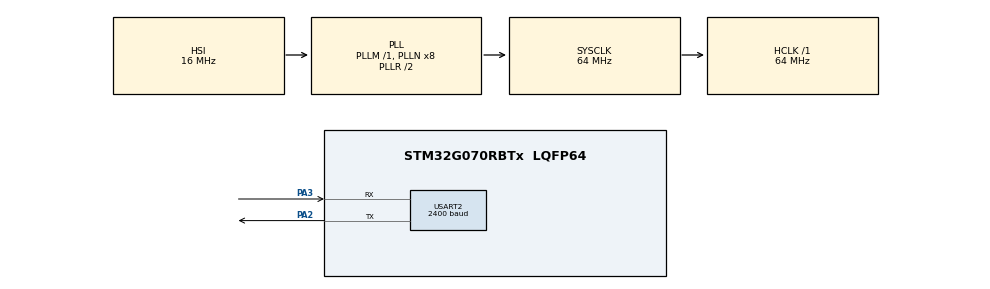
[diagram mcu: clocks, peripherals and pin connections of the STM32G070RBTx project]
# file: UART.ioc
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Mcu.Family=STM32G0
Mcu.Name=STM32G070RBTx
Mcu.Package=LQFP64
NVIC.USART2_IRQn=true\:0\:0\:false\:false\:true\:true\:true
PA13.Mode=Serial_Wire
PA13.Signal=SYS_SWDIO
PA14-BOOT0.Mode=Serial_Wire
PA14-BOOT0.Signal=SYS_SWCLK
PA2.GPIO_PuPd=GPIO_PULLUP
PA2.Mode=Asynchronous
PA2.Signal=USART2_TX
PA3.GPIO_PuPd=GPIO_PULLUP
PA3.Mode=Asynchronous
PA3.Signal=USART2_RX
PC13.Mode=SYS_WakeUp1
PC13.Signal=SYS_WKUP2
PF0-OSC_IN\ (PF0).Mode=HSE-External-Oscillator
PF0-OSC_IN\ (PF0).Signal=RCC_OSC_IN
PF1-OSC_OUT\ (PF1).Mode=HSE-External-Oscillator
PF1-OSC_OUT\ (PF1).Signal=RCC_OSC_OUT
ProjectManager.HeapSize=0x200
ProjectManager.StackSize=0x400
ProjectManager.TargetToolchain=STM32CubeIDE
RCC.ADCFreq_Value=64000000
RCC.AHBFreq_Value=64000000
RCC.CortexFreq_Value=64000000
RCC.EXTERNAL_CLOCK_VALUE=12288000
RCC.HCLKFreq_Value=64000000
RCC.HSE_VALUE=8000000
RCC.HSI_VALUE=16000000
RCC.SYSCLKFreq_VALUE=64000000
RCC.SYSCLKSource=RCC_SYSCLKSOURCE_PLLCLK
RCC.VCOOutputFreq_Value=128000000
USART2.BaudRate=2400
USART2.VirtualMode-Asynchronous=VM_ASYNC
board=NUCLEO-G070RB

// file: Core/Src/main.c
/* USER CODE BEGIN Header */
/**
  ******************************************************************************
  * @file           : main.c
  * @brief          : Main program body
  ******************************************************************************
  * @attention
  *
  * Copyright (c) 2024 STMicroelectronics.
  * All rights reserved.
  *
  * This software is licensed under terms that can be found in the LICENSE file
  * in the root directory of this software component.
  * If no LICENSE file comes with this software, it is provided AS-IS.
  *
  ******************************************************************************
  */
/* USER CODE END Header */
#include "main.h"

/* USER CODE BEGIN Includes */
#include "stdio.h"
#include "string.h"
/* USER CODE END Includes */

/* USER CODE BEGIN PD */
#define EEPROM_BASE_ADDR 0x08080000

#define EEPROM_SIZE 1024
#define MAX_RX_BUFFER_SIZE 1024
/* USER CODE END PD */

UART_HandleTypeDef huart2;

/* USER CODE BEGIN PV */
uint8_t rxBuffer[MAX_RX_BUFFER_SIZE];
uint8_t txBuffer[MAX_RX_BUFFER_SIZE];
uint8_t rxData;
uint32_t rxIndex = 0;
UART_HandleTypeDef huart2;
/* USER CODE END PV */

void SystemClock_Config(void);
static void MX_GPIO_Init(void);
static void MX_USART2_UART_Init(void);
/* USER CODE BEGIN PFP */
void WriteToEEPROM(uint8_t *data, uint32_t size);
void ReadFromEEPROM(uint8_t *data, uint32_t size);
void HAL_UART_RxCpltCallback(UART_HandleTypeDef *huart);
/* USER CODE END PFP */

/* USER CODE BEGIN 0 */

void WriteToEEPROM(uint8_t *data, uint32_t size)
{

  HAL_FLASH_Unlock();

  for (int i = 0; i < size; i++)
  {
    HAL_FLASH_Program(FLASH_TYPEPROGRAM_FAST, EEPROM_SIZE + i, data[i]);
  }

  HAL_FLASH_Lock();
}

void ReadFromEEPROM(uint8_t *data, uint32_t size)
{

  for (int i = 0; i < size; i++)
  {
    data[i] = *(__IO uint8_t *)(EEPROM_SIZE + i);
  }
}

void HAL_UART_RxCpltCallback(UART_HandleTypeDef *huart)
{
  if (huart == &huart2)
  {
    if (rxIndex < MAX_RX_BUFFER_SIZE - 1)
    {
      if (rxData != '\n')
      {
        rxBuffer[rxIndex++] = rxData;
      }
      else
      {
        rxBuffer[rxIndex] = '\0';

        printf("Received data: %s\r\n", rxBuffer);

        WriteToEEPROM(rxBuffer, rxIndex);

        rxIndex = 0;
      }
    }
    HAL_UART_Receive_IT(&huart2, &rxData, 1);
  }
}

int _write(int file, char *ptr, int len)
{
	int DataIdx;

	for(DataIdx=0; DataIdx<len; DataIdx++)
	{
		HAL_UART_Transmit(&huart2, (uint8_t *)ptr++, 1, 100);
	}
	return len;
}

/* USER CODE END 0 */

int main(void)
{

  /* MCU Configuration--------------------------------------------------------*/

  /* Reset of all peripherals, Initializes the Flash interface and the Systick. */
  HAL_Init();

  /* Configure the system clock */
  SystemClock_Config();

  /* Initialize all configured peripherals */
  MX_GPIO_Init();
  MX_USART2_UART_Init();
  /* USER CODE BEGIN 2 */
  HAL_UART_Receive_IT(&huart2, &rxData, 1); // Start UART receive interrupt
  /* USER CODE END 2 */

  /* Infinite loop */
  while (1)
  {

    /* USER CODE BEGIN 3 */

	    if (rxIndex > 0)
	    {
	    	ReadFromEEPROM(txBuffer, EEPROM_SIZE);

	    	// Transmit data over UART
	    	HAL_UART_Transmit(&huart2, txBuffer, EEPROM_SIZE, HAL_MAX_DELAY);

	      // Reset rxIndex to indicate that the data has been transmitted
	      rxIndex = 0;
	    }
  }
  /* USER CODE END 3 */
}

void SystemClock_Config(void)
{
  RCC_OscInitTypeDef RCC_OscInitStruct = {0};
  RCC_ClkInitTypeDef RCC_ClkInitStruct = {0};

  /** Configure the main internal regulator output voltage
  */
  HAL_PWREx_ControlVoltageScaling(PWR_REGULATOR_VOLTAGE_SCALE1);
  /** Initializes the RCC Oscillators according to the specified parameters
  * in the RCC_OscInitTypeDef structure.
  */
  RCC_OscInitStruct.OscillatorType = RCC_OSCILLATORTYPE_HSI;
  RCC_OscInitStruct.HSIState = RCC_HSI_ON;
  RCC_OscInitStruct.HSIDiv = RCC_HSI_DIV1;
  RCC_OscInitStruct.HSICalibrationValue = RCC_HSICALIBRATION_DEFAULT;
  RCC_OscInitStruct.PLL.PLLState = RCC_PLL_ON;
  RCC_OscInitStruct.PLL.PLLSource = RCC_PLLSOURCE_HSI;
  RCC_OscInitStruct.PLL.PLLM = RCC_PLLM_DIV1;
  RCC_OscInitStruct.PLL.PLLN = 8;
  RCC_OscInitStruct.PLL.PLLP = RCC_PLLP_DIV2;
  RCC_OscInitStruct.PLL.PLLR = RCC_PLLR_DIV2;
  if (HAL_RCC_OscConfig(&RCC_OscInitStruct) != HAL_OK)
  {
    Error_Handler();
  }
  /** Initializes the CPU, AHB and APB buses clocks
  */
  RCC_ClkInitStruct.ClockType = RCC_CLOCKTYPE_HCLK|RCC_CLOCKTYPE_SYSCLK
                              |RCC_CLOCKTYPE_PCLK1;
  RCC_ClkInitStruct.SYSCLKSource = RCC_SYSCLKSOURCE_PLLCLK;
  RCC_ClkInitStruct.AHBCLKDivider = RCC_SYSCLK_DIV1;
  RCC_ClkInitStruct.APB1CLKDivider = RCC_HCLK_DIV1;

  if (HAL_RCC_ClockConfig(&RCC_ClkInitStruct, FLASH_LATENCY_2) != HAL_OK)
  {
    Error_Handler();
  }
}

static void MX_USART2_UART_Init(void)
{

  huart2.Instance = USART2;
  huart2.Init.BaudRate = 2400;
  huart2.Init.WordLength = UART_WORDLENGTH_8B;
  huart2.Init.StopBits = UART_STOPBITS_1;
  huart2.Init.Parity = UART_PARITY_NONE;
  huart2.Init.Mode = UART_MODE_TX_RX;
  huart2.Init.HwFlowCtl = UART_HWCONTROL_NONE;
  huart2.Init.OverSampling = UART_OVERSAMPLING_16;
  huart2.Init.OneBitSampling = UART_ONE_BIT_SAMPLE_DISABLE;
  huart2.Init.ClockPrescaler = UART_PRESCALER_DIV1;
  huart2.AdvancedInit.AdvFeatureInit = UART_ADVFEATURE_NO_INIT;
  if (HAL_UART_Init(&huart2) != HAL_OK)
  {
    Error_Handler();
  }
  if (HAL_UARTEx_SetTxFifoThreshold(&huart2, UART_TXFIFO_THRESHOLD_1_8) != HAL_OK)
  {
    Error_Handler();
  }
  if (HAL_UARTEx_SetRxFifoThreshold(&huart2, UART_RXFIFO_THRESHOLD_1_8) != HAL_OK)
  {
    Error_Handler();
  }
  if (HAL_UARTEx_DisableFifoMode(&huart2) != HAL_OK)
  {
    Error_Handler();
  }

}

static void MX_GPIO_Init(void)
{

  /* GPIO Ports Clock Enable */
  __HAL_RCC_GPIOC_CLK_ENABLE();
  __HAL_RCC_GPIOF_CLK_ENABLE();
  __HAL_RCC_GPIOA_CLK_ENABLE();

}

void Error_Handler(void)
{
  __disable_irq();
  while (1)
  {
  }
}
